CM_ "IMPORT _common.dbc"
CM_ "IMPORT _honda_2017.dbc"
CM_ "IMPORT _comma.dbc"

BO_ 145 KINEMATICS: 8 XXX
 SG_ LAT_ACCEL : 7|10@0+ (0.02,-512) [-20|20] "m/s2" EON

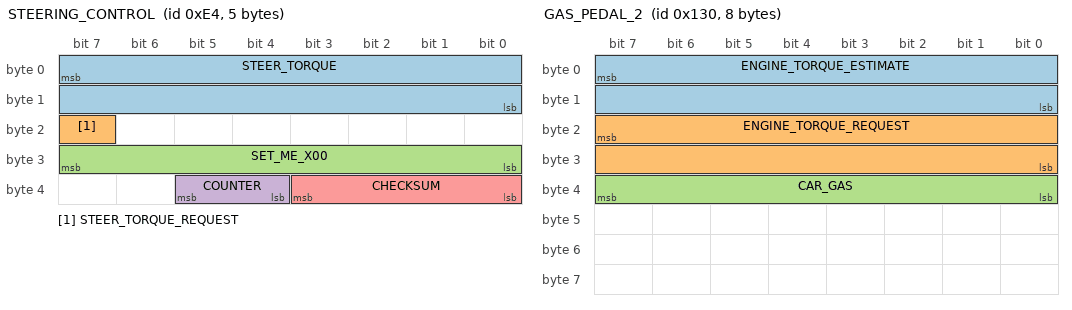
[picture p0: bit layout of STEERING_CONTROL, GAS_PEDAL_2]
BO_ 228 STEERING_CONTROL: 5 ADAS
 SG_ STEER_TORQUE : 7|16@0- (1,0) [-3840|3840] "" EPS
 SG_ STEER_TORQUE_REQUEST : 23|1@0+ (1,0) [0|1] "" EPS
 SG_ SET_ME_X00 : 31|8@0+ (1,0) [0|0] "" EPS
 SG_ COUNTER : 37|2@0+ (1,0) [0|3] "" EPS
 SG_ CHECKSUM : 35|4@0+ (1,0) [0|3] "" EPS

BO_ 304 GAS_PEDAL_2: 8 PCM
 SG_ ENGINE_TORQUE_ESTIMATE : 7|16@0- (1,0) [-1000|1000] "Nm" EON
 SG_ ENGINE_TORQUE_REQUEST : 23|16@0- (1,0) [-1000|1000] "Nm" EON
 SG_ CAR_GAS : 39|8@0+ (1,0) [0|255] "" EON

BO_ 316 GAS_PEDAL: 8 PCM
 SG_ CAR_GAS : 39|8@0+ (1,0) [0|255] "" EON

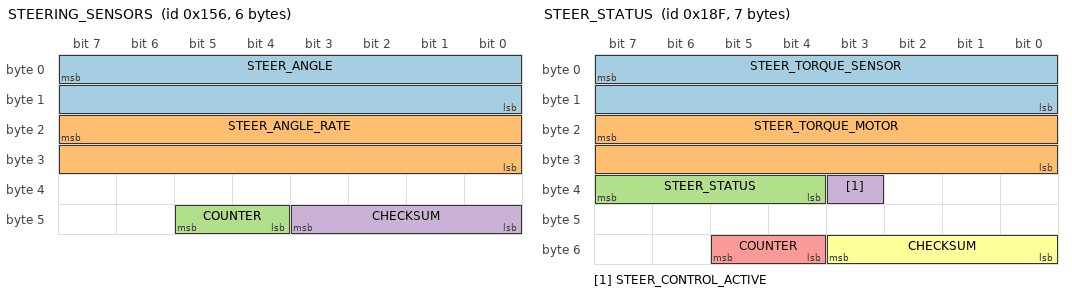
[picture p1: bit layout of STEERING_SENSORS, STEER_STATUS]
BO_ 342 STEERING_SENSORS: 6 EPS
 SG_ STEER_ANGLE : 7|16@0- (-0.1,0) [-500|500] "deg" EON
 SG_ STEER_ANGLE_RATE : 23|16@0- (1,0) [-3000|3000] "deg/s" EON
 SG_ COUNTER : 45|2@0+ (1,0) [0|3] "" EON
 SG_ CHECKSUM : 43|4@0+ (1,0) [0|3] "" EON

BO_ 399 STEER_STATUS: 7 EPS
 SG_ STEER_TORQUE_SENSOR : 7|16@0- (1,0) [-31000|31000] "tbd" EON
 SG_ STEER_TORQUE_MOTOR : 23|16@0- (1,0) [-31000|31000] "tbd" EON
 SG_ STEER_STATUS : 39|4@0+ (1,0) [0|15] "" EON
 SG_ STEER_CONTROL_ACTIVE : 35|1@0+ (1,0) [0|1] "" EON
 SG_ COUNTER : 53|2@0+ (1,0) [0|3] "" EON
 SG_ CHECKSUM : 51|4@0+ (1,0) [0|3] "" EON

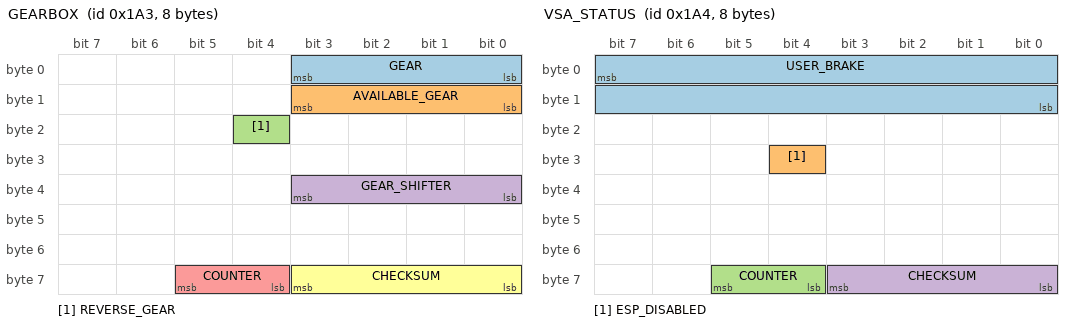
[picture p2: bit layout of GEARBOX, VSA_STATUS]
BO_ 419 GEARBOX: 8 PCM
 SG_ GEAR : 3|4@0+ (1,0) [0|15] "" EON
 SG_ AVAILABLE_GEAR : 11|4@0+ (1,0) [0|15] "" XXX
 SG_ REVERSE_GEAR : 20|1@0+ (-1,1) [0|1] "" XXX
 SG_ GEAR_SHIFTER : 35|4@0+ (1,0) [0|15] "" EON
 SG_ COUNTER : 61|2@0+ (1,0) [0|3] "" EON
 SG_ CHECKSUM : 59|4@0+ (1,0) [0|3] "" EON

BO_ 420 VSA_STATUS: 8 VSA
 SG_ USER_BRAKE : 7|16@0+ (0.015625,-1.609375) [0|1000] "" EON
 SG_ ESP_DISABLED : 28|1@0+ (1,0) [0|1] "" EON
 SG_ COUNTER : 61|2@0+ (1,0) [0|3] "" EON
 SG_ CHECKSUM : 59|4@0+ (1,0) [0|3] "" EON

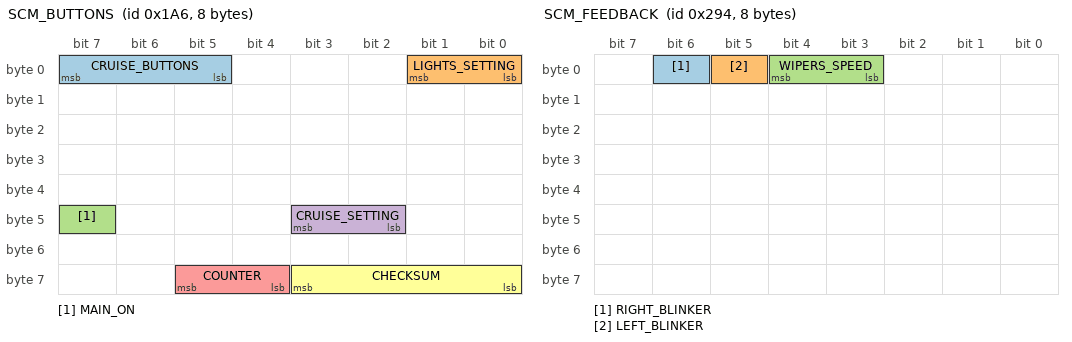
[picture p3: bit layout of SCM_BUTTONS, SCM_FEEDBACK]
BO_ 422 SCM_BUTTONS: 8 SCM
 SG_ CRUISE_BUTTONS : 7|3@0+ (1,0) [0|7] "" EON
 SG_ LIGHTS_SETTING : 1|2@0+ (1,0) [0|3] "" EON
 SG_ MAIN_ON : 47|1@0+ (1,0) [0|1] "" EON
 SG_ CRUISE_SETTING : 43|2@0+ (1,0) [0|3] "" EON
 SG_ COUNTER : 61|2@0+ (1,0) [0|3] "" EON
 SG_ CHECKSUM : 59|4@0+ (1,0) [0|3] "" EON

BO_ 660 SCM_FEEDBACK: 8 SCM
 SG_ RIGHT_BLINKER : 6|1@0+ (1,0) [0|1] "" EON
 SG_ LEFT_BLINKER : 5|1@0+ (1,0) [0|1] "" EON
 SG_ WIPERS_SPEED : 4|2@0+ (1,0) [0|3] "" EON

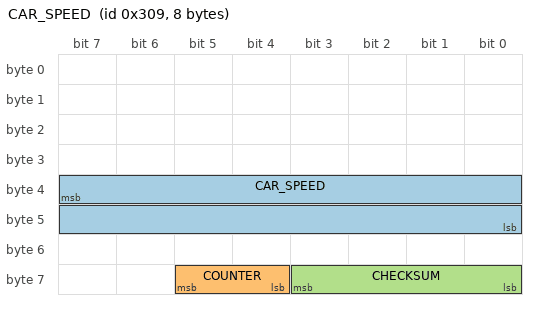
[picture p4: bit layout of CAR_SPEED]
BO_ 777 CAR_SPEED: 8 PCM
 SG_ CAR_SPEED : 39|16@0+ (0.01,0) [0|65535] "kph" XXX
 SG_ COUNTER : 61|2@0+ (1,0) [0|3] "" XXX
 SG_ CHECKSUM : 59|4@0+ (1,0) [0|15] "" XXX

CM_ SG_ 419 GEAR "10 = reverse, 11 = transition/neutral";
CM_ SG_ 419 AVAILABLE_GEAR "gear available at current differential speed";

VAL_ 399 STEER_STATUS 5 "fault" 4 "no_torque_alert_2" 2 "no_torque_alert_1" 0 "normal" ;
VAL_ 419 GEAR 11 "neutral" 10 "reverse" 8 "eighth" 7 "seventh" 6 "sixth" 5 "fifth" 4 "fourth" 3 "third" 2 "second" 1 "first";
VAL_ 419 GEAR_SHIFTER 10 "S" 4 "D" 3 "N" 2 "R" 1 "P" ;
VAL_ 422 CRUISE_BUTTONS 7 "tbd" 6 "tbd" 5 "tbd" 4 "accel_res" 3 "decel_set" 2 "cancel" 1 "main" 0 "none" ;
VAL_ 422 LIGHTS_SETTING 3 "high_beam" 2 "low_beam" 1 "position" 0 "no_lights" ;
VAL_ 422 CRUISE_SETTING 3 "distance_adj" 2 "tbd" 1 "lkas_button" 0 "none" ;

CM_ "CHFFR_METRIC 342 STEER_ANGLE STEER_ANGLE 0.36 180; CHFFR_METRIC 380 ENGINE_RPM ENGINE_RPM 1 0; CHFFR_METRIC 804 ENGINE_TEMPERATURE ENGINE_TEMPERATURE 1 0";
